# SN32F290 register map
Vendor: SONIX; File version: 2026.10.03
CPU: CM0 r0p0, little endian, no MPU, no FPU, 2 interrupt priority bits
Registers are 32-bit, read-write, reset 0x0 unless marked. A register's access mark holds for its fields unless they carry their own. Offsets are from the block's base; [hi:lo] are bit positions; lines under a group give offsets from that group.

## SN_CMP — Comparator
Base 0x40028000
0x00 CTRL reset 0x20002 (reset mask 0x1FFF1FFF) — Offset:0x00 CMP Control Register
  [56:28] CM1G — CMP1 interrupt trigger direction control bit
    0=Falling_range_trigger_2 (CMP1 output status is from high to low as VPREF1 less than CM1N); 1=Rising_edge_trigger_2 (CMP1 output status is from low to high as VPREF1 more than CM1N)
  [53:26] CM1OEN — CMP1 Output pin control bits
    0=Disable_434 (Disable CM1O); 1=P2_2_2 (P2.2 is CM1O and isolate GPIO function); 2=P2_7_6 (P2.7 is CM1O and isolate GPIO function); 3=P3_4_3 (P3.4 is CM1O and isolate GPIO function)
  [46:21] CM1RS — CMP1 internal reference voltage (VIREF1) selection bits
    0=V_00000b_6 (VIREF1=VIREF); 1=V_00001b_2 (VIREF1=VIREF*1/32); 10=V_01010b_4 (VIREF1=VIREF*10/32); 11=V_01011b (VIREF1=VIREF*11/32); 12=V_01100b_3 (VIREF1=VIREF*12/32); 13=V_01101b_4 (VIREF1=VIREF*13/32); 14=V_01110b_3 (VIREF1=VIREF*14/32); 15=V_01111b_3 (VIREF1=VIREF*15/32); 16=V_10000b (VIREF1=VIREF*16/32); 17=V_10001b_5 (VIREF1=VIREF*17/32); 18=V_10010b_4 (VIREF1=VIREF*18/32); 19=V_10011b_2 (VIREF1=VIREF*19/32); 2=V_00010b_3 (VIREF1=VIREF*2/32); 20=V_10100b_6 (VIREF1=VIREF*20/32); 21=V_10101b_6 (VIREF1=VIREF*21/32); 22=V_10110b_4 (VIREF1=VIREF*22/32); 23=V_10111b_4 (VIREF1=VIREF*23/32); 24=V_11000b_2 (VIREF1=VIREF*24/32); 25=V_11001b (VIREF0=VIREF*25/32); 26=V_11010b_3 (VIREF1=VIREF*26/32); 27=V_11011b_2 (VIREF1=VIREF*27/32); 28=V_11100b_5 (VIREF1=VIREF*28/32); 29=V_11101b_3 (VIREF1=VIREF*29/32); 3=V_00011b_5 (VIREF1=VIREF*3/32); 30=V_11110b_5 (VIREF1=VIREF*30/32); 31=V_11111b (VIREF1=VIREF*31/32); 4=V_00100b_3 (VIREF1=VIREF*4/32); 5=V_00101b_2 (VIREF1=VIREF*5/32); 6=V_00110b_2 (VIREF1=VIREF*6/32); 7=V_00111b_6 (VIREF1=VIREF*7/32); 8=V_01000b_4 (VIREF1=VIREF*8/32); 9=V_01001b (VIREF1=VIREF*9/32)
  [39:19] CM1NS — CMP1 Negative input pin
    0=CM1N0; 1=CM1N1; 2=CM1N2; 3=VIREF1 (CM1N0/CM1N1/CM1N2 pins are GPIO mode)
  [35:17] CM1PS — CMP1 Positive input selection bits
    0=No_58 (CM1P0/CM1P1/CM1P2 pins are GPIO mode); 1=CM1P0 (CM1P0 is positive input pin); 2=CM1P1 (CM1P1 is positive input pin); 3=CM1P2 (CM1P2 is positive input pin)
  [32:16] CM1EN — CMP1 Enable bit
    0=Disable_434 (Disable CMP1); 1=Enable_145 (Enable CMP1)
  [24:12] CM0G — CMP0 interrupt trigger direction control bit
    0=Falling_range_trigger_2 (CMP0 output status is from high to low as VPREF0 less than CM0N); 1=Rising_edge_trigger_2 (CMP0 output status is from low to high as VPREF0 more than CM0N)
  [21:10] CM0OEN — CMP0 Output pin control bits
    0=Disable_434 (Disable CM0O); 1=P2_0 (P2.0 is CM0O and isolate GPIO function); 2=P2_6_5 (P2.6 is CM0O and isolate GPIO function); 3=P3_3 (P3.3 is CM0O and isolate GPIO function)
  [14:5] CM0RS — CMP0 internal reference voltage (VIREF0) selection bits
    0=V_00000b_6 (VIREF0=VIREF); 1=V_00001b_2 (VIREF0=VIREF*1/32); 10=V_01010b_4 (VIREF0=VIREF*10/32); 11=V_01011b (VIREF0=VIREF*11/32); 12=V_01100b_3 (VIREF0=VIREF*12/32); 13=V_01101b_4 (VIREF0=VIREF*13/32); 14=V_01110b_3 (VIREF0=VIREF*14/32); 15=V_01111b_3 (VIREF0=VIREF*15/32); 16=V_10000b (VIREF0=VIREF*16/32); 17=V_10001b_5 (VIREF0=VIREF*17/32); 18=V_10010b_4 (VIREF0=VIREF*18/32); 19=V_10011b_2 (VIREF0=VIREF*19/32); 2=V_00010b_3 (VIREF0=VIREF*2/32); 20=V_10100b_6 (VIREF0=VIREF*20/32); 21=V_10101b_6 (VIREF0=VIREF*21/32); 22=V_10110b_4 (VIREF0=VIREF*22/32); 23=V_10111b_4 (VIREF0=VIREF*23/32); 24=V_11000b_2 (VIREF0=VIREF*24/32); 25=V_11001b (VIREF0=VIREF*25/32); 26=V_11010b_3 (VIREF0=VIREF*26/32); 27=V_11011b_2 (VIREF0=VIREF*27/32); 28=V_11100b_5 (VIREF0=VIREF*28/32); 29=V_11101b_3 (VIREF0=VIREF*29/32); 3=V_00011b_5 (VIREF0=VIREF*3/32); 30=V_11110b_5 (VIREF0=VIREF*30/32); 31=V_11111b (VIREF0=VIREF*31/32); 4=V_00100b_3 (VIREF0=VIREF*4/32); 5=V_00101b_2 (VIREF0=VIREF*5/32); 6=V_00110b_2 (VIREF0=VIREF*6/32); 7=V_00111b_6 (VIREF0=VIREF*7/32); 8=V_01000b_4 (VIREF0=VIREF*8/32); 9=V_01001b (VIREF0=VIREF*9/32)
  [7:3] CM0NS — CMP0 Negative input pin
    0=CM0N0 (CM0N0 is negative input pin); 1=CM0N1 (CM0N1 is negative input pin); 2=CM0N2 (CM0N2 is negative input pin); 3=VIREF0 (CM0N0/CM0N1/CM0N2 pins are GPIO mode)
  [3:1] CM0PS — CMP0 Positive input selection bits
    0=No_58 (CM0P0/CM0P1/CM0P2 pins are GPIO mode); 1=CM0P0 (CM0P0 is positive input pin); 2=CM0P1 (CM0P1 is positive input pin); 3=CM0P2 (CM0P2 is positive input pin)
  [0] CM0EN — CMP0 Enable bit
    0=Disable_434 (Disable CMP0); 1=Enable_145 (Enable CMP0)
0x04 CTRL1 reset 0x2 (reset mask 0x1FFF) — Offset:0x04 CMP Control Register 1
  [24:12] CM2G — CMP2 interrupt trigger direction control bit
    0=Falling_range_trigger_2 (CMP2 output status is from high to low as VPREF2 less than CM2N); 1=Rising_edge_trigger_2 (CMP2 output status is from low to high as VPREF2 more than CM2N)
  [21:10] CM2OEN — CMP2 Output pin control bits
    0=Disable_434 (Disable CM2O); 1=P0_12_3 (P0.12 is CM2O and isolate GPIO function); 2=P0_3_4 (P0.3 is CM2O and isolate GPIO function); 3=P3_8 (P3.8 is CM2O and isolate GPIO function)
  [14:5] CM2RS — CMP2 internal reference voltage (VIREF2) selection bits
    0=V_00000b_6 (VIREF2=VIREF); 1=V_00001b_2 (VIREF2=VIREF*1/32); 10=V_01010b_4 (VIREF2=VIREF*10/32); 11=V_01011b (VIREF2=VIREF*11/32); 12=V_01100b_3 (VIREF2=VIREF*12/32); 13=V_01101b_4 (VIREF2=VIREF*13/32); 14=V_01110b_3 (VIREF2=VIREF*14/32); 15=V_01111b_3 (VIREF2=VIREF*15/32); 16=V_10000b (VIREF2=VIREF*16/32); 17=V_10001b_5 (VIREF2=VIREF*17/32); 18=V_10010b_4 (VIREF2=VIREF*18/32); 19=V_10011b_2 (VIREF2=VIREF*19/32); 2=V_00010b_3 (VIREF2=VIREF*2/32); 20=V_10100b_6 (VIREF2=VIREF*20/32); 21=V_10101b_6 (VIREF2=VIREF*21/32); 22=V_10110b_4 (VIREF2=VIREF*22/32); 23=V_10111b_4 (VIREF2=VIREF*23/32); 24=V_11000b_2 (VIREF2=VIREF*24/32); 25=V_11001b (VIREF2=VIREF*25/32); 26=V_11010b_3 (VIREF2=VIREF*26/32); 27=V_11011b_2 (VIREF2=VIREF*27/32); 28=V_11100b_5 (VIREF2=VIREF*28/32); 29=V_11101b_3 (VIREF2=VIREF*29/32); 3=V_00011b_5 (VIREF2=VIREF*3/32); 30=V_11110b_5 (VIREF2=VIREF*30/32); 31=V_11111b (VIREF2=VIREF*31/32); 4=V_00100b_3 (VIREF2=VIREF*4/32); 5=V_00101b_2 (VIREF2=VIREF*5/32); 6=V_00110b_2 (VIREF2=VIREF*6/32); 7=V_00111b_6 (VIREF2=VIREF*7/32); 8=V_01000b_4 (VIREF2=VIREF*8/32); 9=V_01001b (VIREF2=VIREF*9/32)
  [7:3] CM2NS — CMP2 Negative input pin
    0=CM2N0; 1=CM2N1; 2=CM2N2; 3=VIREF2 (CM2N0/CM2N1/CM2N2 pins are GPIO mode)
  [3:1] CM2PS — CMP2 Positive input selection bits
    0=No_58 (CM2P0/CM2P1/CM2P2 pins are GPIO mode); 1=CM2P0 (CM2P0 is positive input pin); 2=CM2P1 (CM2P1 is positive input pin); 3=CM2P2 (CM2P2 is positive input pin)
  [0] CM2EN — CMP2 Enable bit
    0=Disable_434 (Disable CMP2); 1=Enable_145 (Enable CMP2)
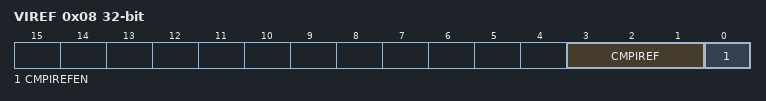
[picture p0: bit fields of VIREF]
0x08 VIREF (reset mask 0x7) — Offset:0x08 CMP Internal Reference Voltage register
  [3:1] CMPIREF — CMP internal reference voltage (VIREF) source
    0=VDD_2 (VIREF=VDD); 1=Internal_1P5V (VIREF=Internal 1P5V); 2=Internal_2V (VIREF=Internal 2V); 3=Internal_3V (VIREF=Internal 3V)
  [0] CMPIREFEN — CMP internal reference voltage (VIREF) enable
    0=Disable_434 (Disable CMP internal reference voltage); 1=Enable_145 (Enable CMP internal reference voltage)
0x0C OS ro (reset mask 0x7) — Offset:0xC CMP Output Status Register
  [4:2] CM2OUT — CMP2 Output flag bit
    0=CMP2_V_is_less_than_V (V2+ is less than V2- voltage); 1=CMP2_V_is_more_than_V (V2+ is more than V2- voltage)
  [2:1] CM1OUT — CMP1 Output flag bit
    0=CMP1_V_is_less_than_V (V1+ is less than V1-); 1=CMP1_V_is_more_than_V (V1+ is more than V1- voltage)
  [0] CM0OUT — CMP0 Output flag bit
    0=CMP0_V_is_less_than_V (V0+ is less than V0-); 1=CMP0_V_is_more_than_V (V0+ is more than V0-)
0x10 IE (reset mask 0xF) — Offset:0x10 CMP Interrupt Enable Register
  [6:3] CSIE — Cap-sensing interrupt enable
    0=Disable_434 (Disable CS interrupt); 1=Enable_145 (Enable CS interrupt)
  [4:2] CM2IE — CMP2 interrupt enable
    0=Disable_434 (Disable CMP2 interrupt); 1=Enable_145 (Enable CMP2 interrupt)
  [2:1] CM1IE — CMP1 interrupt enable
    0=Disable_434 (Disable CMP1 interrupt); 1=Enable_145 (Enable CMP1 interrupt)
  [0] CM0IE — CMP0 interrupt enable
    0=Disable_434 (Disable CMP0 interrupt); 1=Enable_145 (Enable CMP0 interrupt)
0x14 RIS ro (reset mask 0xF) — Offset:0x14 CMP n Raw Interrupt Status Register
  [6:3] CSIF — Cap-sensing raw interrupt flag
    0=No_interrupt_21 (No interrupt on Cap-sensing function); 1=Met_interrupt_requirements_37 (Interrupt requirements met on Cap-sensing function)
  [4:2] CM2IF — CMP2 raw interrupt flag
    0=No_interrupt_21 (No interrupt on CMP2); 1=Met_interrupt_requirements_37 (Interrupt requirements met on CMP2)
  [2:1] CM1IF — CMP1 raw interrupt flag
    0=No_interrupt_21 (No interrupt on CMP1); 1=Met_interrupt_requirements_37 (Interrupt requirements met on CMP1)
  [0] CM0IF — CMP0 raw interrupt flag
    0=No_interrupt_21 (No interrupt on CMP0); 1=Met_interrupt_requirements_37 (Interrupt requirements met on CMP0)
0x18 IC wo (reset mask 0xF) — Offset:0x18 CMP Interrupt Clear Register
  [6:3] CSIC — Cap-sensing interrupt flag clear bit
    0=No_effect_200; 1=Clear_V_150 (Clear CS interrupt flag)
  [4:2] CM2IC — CMP2 interrupt flag clear bit
    0=No_effect_200; 1=Clear_V_150 (Clear CMP2 interrupt flag)
  [2:1] CM1IC — CMP1 interrupt flag clear bit
    0=No_effect_200; 1=Clear_V_150 (Clear CMP1 interrupt flag)
  [0] CM0IC — CMP0 interrupt flag clear bit
    0=No_effect_200; 1=Clear_V_150 (Clear CMP0 interrupt flag)
0x1C DB (reset mask 0x1F777) — Offset:0x1C CMP Interrupt Clear Register
  [28:12] CSDB — Count for Cap-sensing output debounce time
    0=V_00000b_6 (No Cap-sening output debounce time); 1=V_00001b_2 (Cap-sensing output debounce time=1*CS_PCLK); 10=V_01010b_4 (Cap-sensing output debounce time=10*CS_PCLK); 11=V_01011b (Cap-sensing output debounce time=11*CS_PCLK); 12=V_01100b_3 (Cap-sensing output debounce time=12*CS_PCLK); 13=V_01101b_4 (Cap-sensing output debounce time=13*CS_PCLK); 14=V_01110b_3 (Cap-sensing output debounce time=14*CS_PCLK); 15=V_01111b_3 (Cap-sensing output debounce time=15*CS_PCLK); 16=V_10000b (Cap-sensing output debounce time=16*CS_PCLK); 17=V_10001b_5 (Cap-sensing output debounce time=17*CS_PCLK); 18=V_10010b_4 (Cap-sensing output debounce time=18*CS_PCLK); 19=V_10011b_2 (Cap-sensing output debounce time=19*CS_PCLK); 2=V_00010b_3 (Cap-sensing output debounce time=2*CS_PCLK); 20=V_10100b_6 (Cap-sensing output debounce time=20*CS_PCLK); 21=V_10101b_6 (Cap-sensing output debounce time=21*CS_PCLK); 22=V_10110b_4 (Cap-sensing output debounce time=22*CS_PCLK); 23=V_10111b_4 (Cap-sensing output debounce time=23*CS_PCLK); 24=V_11000b_2 (Cap-sensing output debounce time=24*CS_PCLK); 25=V_11001b (Cap-sensing output debounce time=25*CS_PCLK); 26=V_11010b_3 (Cap-sensing output debounce time=26*CS_PCLK); 27=V_11011b_2 (Cap-sensing output debounce time=27*CS_PCLK); 28=V_11100b_5 (Cap-sensing output debounce time=28*CS_PCLK); 29=V_11101b_3 (Cap-sensing output debounce time=29*CS_PCLK); 3=V_00011b_5 (Cap-sensing output debounce time=3*CS_PCLK); 30=V_11110b_5 (Cap-sensing output debounce time=30*CS_PCLK); 31=V_11111b (Cap-sensing output debounce time=31*CS_PCLK); 4=V_00100b_3 (Cap-sensing output debounce time=4*CS_PCLK); 5=V_00101b_2 (Cap-sensing output debounce time=5*CS_PCLK); 6=V_00110b_2 (Cap-sensing output debounce time=6*CS_PCLK); 7=V_00111b_6 (Cap-sensing output debounce time=7*CS_PCLK); 8=V_01000b_4 (Cap-sensing output debounce time=8*CS_PCLK); 9=V_01001b (Cap-sensing output debounce time=9*CS_PCLK)
  [18:8] CM2DB — Count for CMP2 output debounce time
    0=V_000b_5 (No CMP2 output debounce time); 1=V_001b_13 (CMP2 output debounce time=2*CMP2_PCLK); 2=V_010b_18 (CMP2 output debounce time=4*CMP2_PCLK); 3=V_011b_3 (CMP2 output debounce time=8*CMP2_PCLK); 4=V_100b (CMP2 output debounce time=16*CMP2_PCLK); 5=V_101b_5 (CMP2 output debounce time=32*CMP2_PCLK); 6=V_110b (CMP2 output debounce time=64*CMP2_PCLK); 7=V_111b_11 (CMP2 output debounce time=128*CMP2_PCLK)
  [10:4] CM1DB — Count for CMP1 output debounce time
    0=V_000b_5 (No CMP1 output debounce time); 1=V_001b_13 (CMP1 output debounce time=2*CMP1_PCLK); 2=V_010b_18 (CMP1 output debounce time=4*CMP1_PCLK); 3=V_011b_3 (CMP1 output debounce time=8*CMP1_PCLK); 4=V_100b (CMP1 output debounce time=16*CMP1_PCLK); 5=V_101b_5 (CMP1 output debounce time=32*CMP1_PCLK); 6=V_110b (CMP1 output debounce time=64*CMP1_PCLK); 7=V_111b_11 (CMP1 output debounce time=128*CMP1_PCLK)
  [2:0] CM0DB — Count for CMP0 output debounce time
    0=V_000b_5 (No CMP0 output debounce time); 1=V_001b_13 (CMP0 output debounce time=2*CMP0_PCLK); 2=V_010b_18 (CMP0 output debounce time=4*CMP0_PCLK); 3=V_011b_3 (CMP0 output debounce time=8*CMP0_PCLK); 4=V_100b (CMP0 output debounce time=16*CMP0_PCLK); 5=V_101b_5 (CMP0 output debounce time=32*CMP0_PCLK); 6=V_110b (CMP0 output debounce time=64*CMP0_PCLK); 7=V_111b_11 (CMP0 output debounce time=128*CMP0_PCLK)
0x20 CSCTRL reset 0x47600 (reset mask 0xC7FFF8FF) — Offset:0x20 CMP Cap-sensing Control Register
  [62:31] CSRDY ro — Cap-sensing module ready flag
    0=Not_Ready_4 (Cap-sensing module are not ready); 1=Ready_8 (Cap-sensing module are ready)
  [60:30] CSFAPC — CSF active controll
    0=Disable_434 (CSF can be triggered any time); 1=Enable_145 (CSF can be triggered while CSS is high.)
  [52:26] CSDIS — Channel discharge signl (CK_TCH) controll bit
    0=Enable_145; 1=Disable_434
  [50:25] CSOUTEN — Cap-sening output pin enable bit
    0=Disable_434 (CSOUT pin is GPIO); 1=Enable_145 (CSOUT pin is Cap-sensing output pin)
  [48:24] CCAL4 — Cap Calibration select bit
    0=VSS (Cap Calibration circuit is connect to VSS); 1=VDD_2 (Cap Calibration circuit is connect to VDD)
  [43:20] CCAL — Cap Calibration parameter
    0=V_0000b_19 (0pF); 1=V_0001b_14 (0.2pF); 10=V_1010b_2 (2.0pF); 11=V_1011b_18 (2.2pF); 12=V_1100b_24 (2.4pF); 13=V_1101b (2.6pF); 14=V_1110b_12 (2.8pF); 15=V_1111b_28 (3.0pF); 2=V_0010b_12 (0.4pF); 3=V_0011b_12 (0.6pF); 4=V_0100b_7 (0.8pF); 5=V_0101b_14 (1.0pF); 6=V_0110b_4 (1.2pF); 7=V_0111b_5 (1.4pF); 8=V_1000b_17 (1.6pF); 9=V_1001b (1.8pF)
  [37:18] TNON — Non-overlap time
    0=V_0_164 (13ns); 1=V_1_374 (26ns); 2=V_2 (39ns); 3=V_3_20 (52ns)
  [32:15] CHG — Cap-sensing charging time
    0=V_000b_5 (2us); 1=V_001b_13 (4us); 2=V_010b_18 (8us); 3=V_011b_3 (16us); 4=V_100b (32us); 5=V_101b_5 (64us); 6=V_110b (128us); 7=V_111b_11 (256us)
  [28:14] VDSEL — Cap-sensing voltage detects select bit
    1=Comparator (Cap-sensing voltage is detected by Comparator)
  [24:11] CMP — Comparator reference control bits
    0=V_000b_5 (0.3083*VREG33); 1=V_001b_13 (0.3583*VREG33); 2=V_010b_18 (0.3917*VREG33); 3=V_011b_3 (0.4417*VREG33); 4=V_100b (0.5083*VREG33); 5=V_101b_5 (0.5583*VREG33); 6=V_110b (0.5917*VREG33); 7=V_111b_11 (0.6417*VREG33)
  [10:3] CSH — Cap-sensing channel
    0=V_00000b_6 (CT0); 1=V_00001b_2 (CT1); 10=V_01010b_4 (CT10); 11=V_01011b (CT11); 12=V_01100b_3 (CT12); 13=V_01101b_4 (CT13); 14=V_01110b_3 (CT14); 15=V_01111b_3 (CT15); 16=V_10000b (CT16); 17=V_10001b_5 (CT17); 18=V_10010b_4 (CT18); 19=V_10011b_2 (CT19); 2=V_00010b_3 (CT2); 20=V_10100b_6 (CT20); 21=V_10101b_6 (CT21); 22=V_10110b_4 (CT22); 23=V_10111b_4 (CT23); 24=V_11000b_2 (CT24 (Internal reference channel)); 3=V_00011b_5 (CT3); 4=V_00100b_3 (CT4); 5=V_00101b_2 (CT5); 6=V_00110b_2 (CT6); 7=V_00111b_6 (CT7); 8=V_01000b_4 (CT8); 9=V_01001b (CT9)
  [4:2] CS1ST — Cap-sensing channel scan group start bit
    0=Not_New (Not group scan start); 1=New_V (New group scan start)
  [2:1] CSS — Cap-sensing operation start bit
    0=Stop_5 (Cap-sensing operation stops); 1=Start_2 (Cap-sensing operation starts)
  [0] CSEN — Cap-sensing module enable bit
    0=Disable_434 (Disable CS module); 1=Enable_145 (Enable CS module)
0x24 CSCTRL1 (reset mask 0x7FC3) — Offset:0x24 CMP Cap-sensing Control Register 1
  [28:14] CSCOV — CSC 16-bit timer counter overflow indicator (Clock source is CS_PCLK)
    0=No_58 (No overflow); 1=Overflow_2 (CSC[15:0] timer counter overflows)
  [26:13] CSVCOV — CSV 16-bit event counter overflow indicator (Clock source is Cap-sensing 4MHz)
    0=No_58 (No overflow); 1=Overflow_2 (CSV[15:0] event counter overflows)
  [20:8] OSCR — Ring OSC.4MHz clock range
    0=V_00000b_6 (4.096MHz); 1=V_00001b_2 (3.973MHz); 10=V_01010b_4 (4.427MHz); 11=V_01011b (4.299MHz); 12=V_01100b_3 (3.808MHz); 13=V_01101b_4 (3.714MHz); 14=V_01110b_3 (3.715MHz); 15=V_01111b_3 (3.626MHz); 16=V_10000b (5.157MHz); 17=V_10001b_5 (5.004MHz); 18=V_10010b_4 (5.004MHz); 19=V_10011b_2 (4.860MHz); 2=V_00010b_3 (3.973MHz); 20=V_10100b_6 (4.308MHz); 21=V_10101b_6 (4.203MHz); 22=V_10110b_4 (4.203MHz); 23=V_10111b_4 (4.103MHz); 24=V_11000b_2 (6.416MHz); 25=V_11001b (6.227MHz); 26=V_11010b_3 (6.227MHz); 27=V_11011b_2 (6.051MHz); 28=V_11100b_5 (5.372MHz); 29=V_11101b_3 (5.243MHz); 3=V_00011b_5 (3.857MHz); 30=V_11110b_5 (5.243MHz); 31=V_11111b (5.120MHz); 4=V_00100b_3 (3.414MHz); 5=V_00101b_2 (3.329MHz); 6=V_00110b_2 (3.330MHz); 7=V_00111b_6 (3.250MHz); 8=V_01000b_4 (4.564MHz); 9=V_01001b (4.428MHz)
  [13:6] SGSEL — Cap-sensing 4MHz clock source and SSCG select bit
    0=V_00b_23 (4MHz IHRC and disable PRBS function); 2=V_10b_60 (4MHz Ring OSC. and disable PRBS function)
  [1:0] SGFRQ — Spread Spectrum frequency
    0=V_00b_23 (4MHz); 1=V_01b (2MHz); 2=V_10b_60 (1MHz); 3=V_11b_31 (0.5MHz)
0x28 CSCNT ro — Offset:0x28 CMP CapSensing Counter Register
  [47:16] CSC — CSC 16-bit timer counter (CSC counter clock source is CS_PCLK)
  [15:0] CSV — CSV 16-bit event counter (CSV counter clock source is CS_4MHz)
